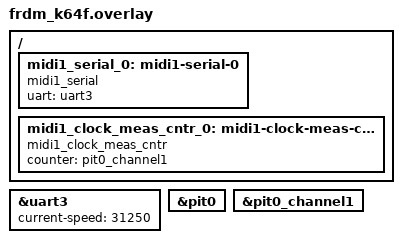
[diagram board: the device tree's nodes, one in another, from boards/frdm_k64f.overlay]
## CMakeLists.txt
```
# SPDX-License-Identifier: Apache-2.0

# MIDI 1.0 Clock Measurement Sample
cmake_minimum_required(VERSION 3.20.0)

find_package(Zephyr REQUIRED HINTS $ENV{ZEPHYR_BASE})
project(midi1_clock_measurement)

target_sources(app PRIVATE src/main.c)
```

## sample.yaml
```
# SPDX-License-Identifier: Apache-2.0

sample:
  name: MIDI 1.0 Clock Measurement
tests:
  sample.midi1_clock_meas:
    platform_allow:
      - frdm_k64f
      - frdm_mcxc242
    harness: console
    harness_config:
      type: one_line
      regex:
        - "Incoming Clock: (.*) BPM"
```

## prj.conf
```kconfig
# SPDX-License-Identifier: Apache-2.0

# MIDI 1.0 Clock Measurement Configuration
CONFIG_MIDI1_CLOCK_MEAS_CNTR=y
CONFIG_MIDI1_SERIAL=y
CONFIG_LOG=y
CONFIG_MIDI1_HARMONIC=y
```

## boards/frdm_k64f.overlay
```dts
/*
 * SPDX-License-Identifier: Apache-2.0
 */

/**
 * @file frdm_k64f.overlay
 * @brief overlay for MIDI1 clock measurement
 * @author Jan-Willem Smaal <usenet@gispen.org>
 */

/ {
	midi1_serial_0: midi1-serial-0 {
		compatible = "midi1_serial";
		uart = <&uart3>;
		status = "okay";
	};

	midi1_clock_meas_cntr_0: midi1-clock-meas-cntr-0 {
		compatible = "midi1_clock_meas_cntr";
		counter = <&pit0_channel1>;
		status = "okay";
	};
};

&uart3 {
	status = "okay";
	/* MIDI baud rate */
	current-speed = <31250>;
};

&pit0 {
	status = "okay";
};

&pit0_channel1 {
	status = "okay";
};

/* EOF */
```

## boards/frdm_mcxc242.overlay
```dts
/*
 * SPDX-License-Identifier: Apache-2.0
 */

/**
 * @file frdm_mcxc242.overlay
 * @brief overlay for MIDI1 clock measurement on MCXC242
 * @author Jan-Willem Smaal <usenet@gispen.org>
 */

/ {
	midi1_serial_0: midi1-serial-0 {
		compatible = "midi1_serial";
		uart = <&lpuart0>;
		status = "okay";
	};

	midi1_clock_meas_cntr_0: midi1-clock-meas-cntr-0 {
		compatible = "midi1_clock_meas_cntr";
		counter = <&pit0_channel1>;
		status = "okay";
	};
};

&lpuart0 {
	status = "okay";
	current-speed = <31250>;
};

&pit0 {
	status = "okay";
};

&pit0_channel1 {
	status = "okay";
};

/* EOF */
```

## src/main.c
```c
/*
 * SPDX-License-Identifier: Apache-2.0
 */

/**
 * @file main.c
 * @brief MIDI 1.0 Clock Measurement Sample Application
 *
 * This sample demonstrates how to use the midi1_clock_meas_cntr driver
 * to measure the BPM of an incoming MIDI timing clock signal.
 * It uses midi1_serial to receive the 0xF8 bytes and pulse the driver.
 */

#include <zephyr/kernel.h>
#include <zephyr/device.h>
#include <zephyr/drivers/midi/midi1.h>
#include <zephyr/drivers/midi/midi1_serial.h>
#include <zephyr/drivers/midi/midi1_clock_meas_cntr.h>
#include <zephyr/logging/log.h>

LOG_MODULE_REGISTER(midi1_clock_meas_sample, LOG_LEVEL_INF);

static const struct device *meas_dev;

/* Callback when a MIDI Realtime message is received */
static void midi1_realtime_callback(uint8_t msg)
{
	if (msg == RT_TIMING_CLOCK) {
		/* Notify the measurement driver that a pulse arrived */
		midi1_clock_meas_cntr_pulse(meas_dev);
	}
}

int main(void)
{
	const struct device *midi_serial = DEVICE_DT_GET_ANY(midi1_serial);
	const struct midi1_clock_meas_cntr_api *meas_api;
	char bpm_str[16];
	struct midi1_serial_callbacks cb = {0};

	meas_dev = DEVICE_DT_GET_ANY(midi1_clock_meas_cntr);

	if (meas_dev == NULL || midi_serial == NULL) {
		LOG_ERR("Required devices not found in devicetree");
		return -ENODEV;
	}

	meas_api = (const struct midi1_clock_meas_cntr_api *)meas_dev->api;

	if (!device_is_ready(meas_dev)) {
		LOG_ERR("MIDI measurement device %s is not ready", meas_dev->name);
		return -ENODEV;
	}

	if (!device_is_ready(midi_serial)) {
		LOG_ERR("MIDI serial device %s is not ready", midi_serial->name);
		return -ENODEV;
	}

	/* Register real-time callback to catch the 0xF8 bytes */
	cb.realtime = midi1_realtime_callback;
	midi1_serial_register_callbacks(midi_serial, &cb);

	LOG_INF("Starting MIDI Clock Measurement...");

	int64_t last_log_time = 0;

	/* Start a thread or loop for the parser */
	while (1) {
		/* This is a blocking call that parses incoming MIDI bytes */
		midi1_serial_receiveparser(midi_serial);

		int64_t now = k_uptime_get();
		if (now - last_log_time >= 1000) {
			if (meas_api->is_valid(meas_dev)) {
				uint16_t current_bpm = meas_api->get_sbpm(meas_dev);
				sbpm_to_str(current_bpm, bpm_str, sizeof(bpm_str));
				LOG_INF("Incoming Clock: %s BPM", bpm_str);
			} else {
				LOG_INF("Waiting for MIDI clock pulses...");
			}
			last_log_time = now;
		}
	}

	return 0;
}
```
